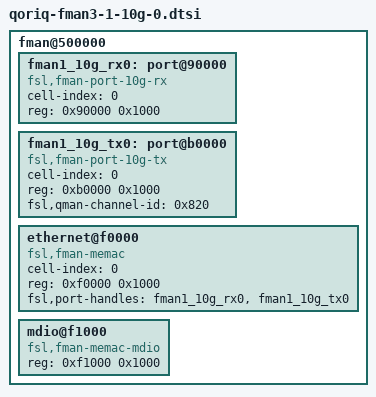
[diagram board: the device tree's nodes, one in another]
/*
 * QorIQ FMan v3 10g port #0 device tree stub [ controller @ offset 0x500000 ]
 *
 * Copyright 2012 Freescale Semiconductor Inc.
 *
 * Redistribution and use in source and binary forms, with or without
 * modification, are permitted provided that the following conditions are met:
 *     * Redistributions of source code must retain the above copyright
 *       notice, this list of conditions and the following disclaimer.
 *     * Redistributions in binary form must reproduce the above copyright
 *       notice, this list of conditions and the following disclaimer in the
 *       documentation and/or other materials provided with the distribution.
 *     * Neither the name of Freescale Semiconductor nor the
 *       names of its contributors may be used to endorse or promote products
 *       derived from this software without specific prior written permission.
 *
 *
 * ALTERNATIVELY, this software may be distributed under the terms of the
 * GNU General Public License ("GPL") as published by the Free Software
 * Foundation, either version 2 of that License or (at your option) any
 * later version.
 *
 * THIS SOFTWARE IS PROVIDED BY Freescale Semiconductor ``AS IS'' AND ANY
 * EXPRESS OR IMPLIED WARRANTIES, INCLUDING, BUT NOT LIMITED TO, THE IMPLIED
 * WARRANTIES OF MERCHANTABILITY AND FITNESS FOR A PARTICULAR PURPOSE ARE
 * DISCLAIMED. IN NO EVENT SHALL Freescale Semiconductor BE LIABLE FOR ANY
 * DIRECT, INDIRECT, INCIDENTAL, SPECIAL, EXEMPLARY, OR CONSEQUENTIAL DAMAGES
 * (INCLUDING, BUT NOT LIMITED TO, PROCUREMENT OF SUBSTITUTE GOODS OR SERVICES;
 * LOSS OF USE, DATA, OR PROFITS; OR BUSINESS INTERRUPTION) HOWEVER CAUSED AND
 * ON ANY THEORY OF LIABILITY, WHETHER IN CONTRACT, STRICT LIABILITY, OR TORT
 * (INCLUDING NEGLIGENCE OR OTHERWISE) ARISING IN ANY WAY OUT OF THE USE OF THIS
 * SOFTWARE, EVEN IF ADVISED OF THE POSSIBILITY OF SUCH DAMAGE.
 */

fman@500000 {
	fman1_10g_rx0: port@90000 {
		cell-index = <0>;
		compatible = "fsl,fman-port-10g-rx";
		reg = <0x90000 0x1000>;
	};

	fman1_10g_tx0: port@b0000 {
		cell-index = <0>;
		compatible = "fsl,fman-port-10g-tx";
		reg = <0xb0000 0x1000>;
		fsl,qman-channel-id = <0x820>;
	};

	ethernet@f0000 {
		cell-index = <0>;
		compatible = "fsl,fman-memac";
		reg = <0xf0000 0x1000>;
		fsl,port-handles = <&fman1_10g_rx0 &fman1_10g_tx0>;
	};

	mdio@f1000 {
                #address-cells = <1>;
                #size-cells = <0>;
		compatible = "fsl,fman-memac-mdio";
                reg = <0xf1000 0x1000>;
	};
};
